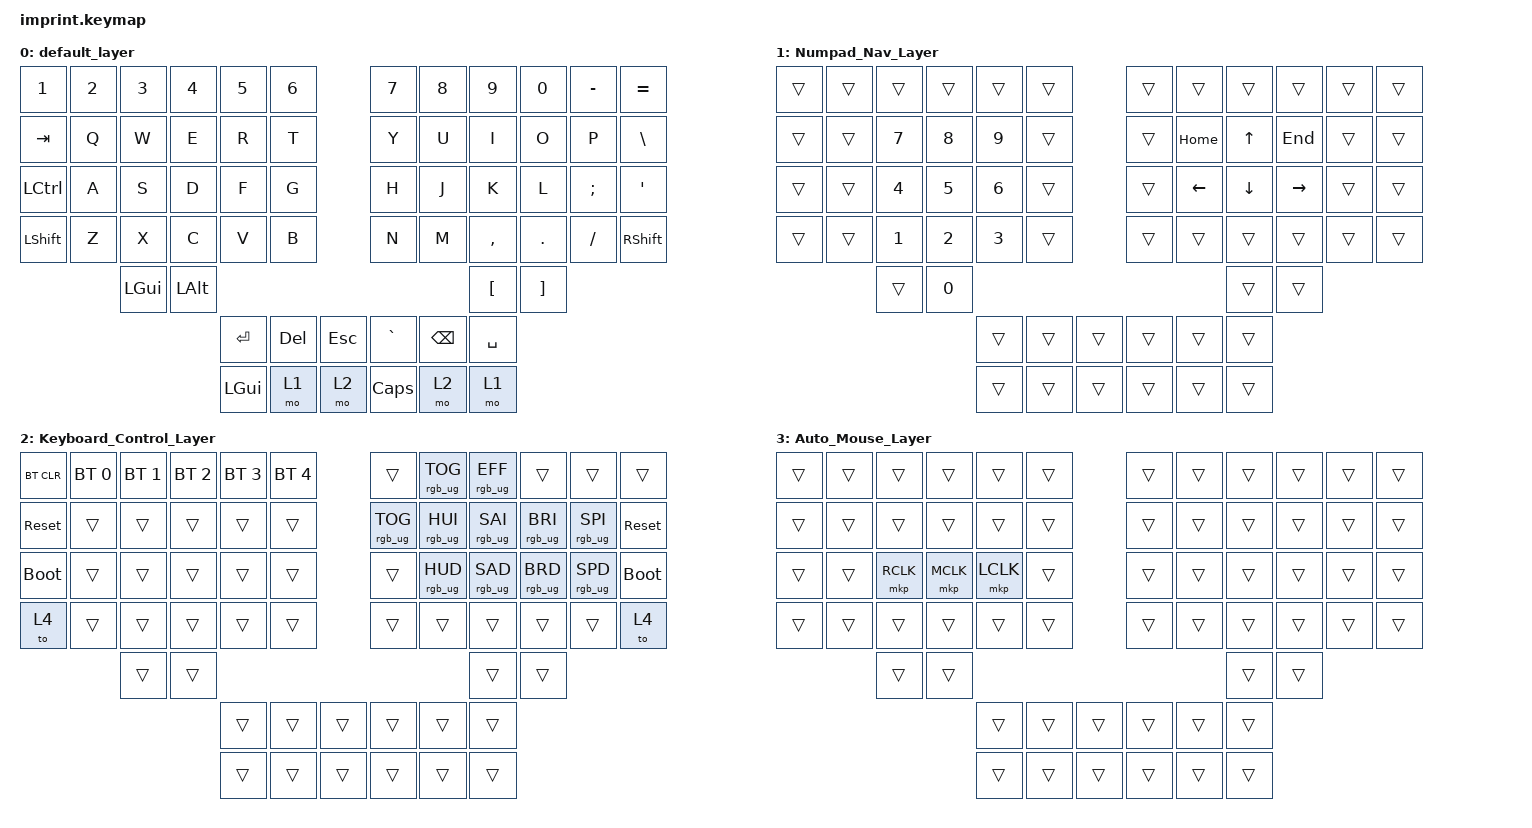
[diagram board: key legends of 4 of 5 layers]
#include <input/processors.dtsi>
#include <dt-bindings/zmk/input_transform.h>
#include <behaviors.dtsi>
#include <dt-bindings/zmk/bt.h>
#include <dt-bindings/zmk/keys.h>
#include <dt-bindings/zmk/pointing.h>
#include <dt-bindings/zmk/rgb.h>

#include "imprint-layout.dtsi"
/ {
//    chosen { zmk,matrix-transform = &imprint_function_row_full_bottom_row; };

    keymap {
        compatible = "zmk,keymap";

        default_layer {
            bindings = <
&kp N1  &kp N2    &kp N3    &kp N4    &kp N5              &kp N6     &kp N7    &kp N8     &kp N9    &kp N0    &kp MINUS &kp EQUAL
&kp TAB    &kp Q   &kp W     &kp E     &kp R     &kp T               &kp Y      &kp U     &kp I      &kp O     &kp P     &kp BSLH
&kp LCTRL  &kp A   &kp S     &kp D     &kp F     &kp G               &kp H      &kp J     &kp K      &kp L     &kp SEMI  &kp SQT
&kp LSHFT  &kp Z   &kp X     &kp C     &kp V     &kp B               &kp N      &kp M     &kp COMMA  &kp DOT   &kp FSLH  &kp RSHFT
                &kp LGUI  &kp LALT                                                        &kp LBKT   &kp RBKT
                                       &kp RET   &kp DEL  &kp ESC    &kp GRAVE  &kp BSPC  &kp SPACE
                                       &kp LGUI  &mo 1    &mo 2      &kp CAPS   &mo 2     &mo 1
            >;
        };

        Numpad_Nav_Layer {
            bindings = <
&trans  &trans  &trans  &trans  &trans  &trans            &trans  &trans    &trans    &trans     &trans  &trans
&trans  &trans  &kp N7  &kp N8  &kp N9  &trans            &trans  &kp HOME  &kp UP    &kp END    &trans  &trans
&trans  &trans  &kp N4  &kp N5  &kp N6  &trans            &trans  &kp LEFT  &kp DOWN  &kp RIGHT  &trans  &trans
&trans  &trans  &kp N1  &kp N2  &kp N3  &trans            &trans  &trans    &trans    &trans     &trans  &trans
                &trans  &kp N0                                              &trans    &trans
                                &trans  &trans  &trans    &trans  &trans    &trans
                                &trans  &trans  &trans    &trans  &trans    &trans
            >;
        };

        Keyboard_Control_Layer {
            bindings = <
&bt BT_CLR   &bt BT_SEL 0  &bt BT_SEL 1  &bt BT_SEL 2  &bt BT_SEL 3  &bt BT_SEL 4            &trans  &rgb_ug RGB_TOG  &rgb_ug RGB_EFF  &trans           &trans           &trans
&sys_reset   &trans        &trans        &trans        &trans        &trans                  &rgb_ug RGB_TOG  &rgb_ug RGB_HUI  &rgb_ug RGB_SAI  &rgb_ug RGB_BRI  &rgb_ug RGB_SPI  &sys_reset
&bootloader  &trans        &trans        &trans        &trans        &trans                  &trans  &rgb_ug RGB_HUD  &rgb_ug RGB_SAD  &rgb_ug RGB_BRD  &rgb_ug RGB_SPD  &bootloader
&to 4        &trans        &trans        &trans        &trans        &trans                  &trans  &trans           &trans           &trans           &trans           &to 4
                            &trans        &trans                                                                     &trans           &trans
                                                       &trans        &trans        &trans    &trans  &trans           &trans
                                                       &trans        &trans        &trans    &trans  &trans           &trans
            >;
        };

        Auto_Mouse_Layer {
            bindings = <
&trans  &trans  &trans     &trans     &trans     &trans            &trans  &trans  &trans  &trans  &trans  &trans
&trans  &trans  &trans     &trans     &trans     &trans            &trans  &trans  &trans  &trans  &trans  &trans
&trans  &trans  &mkp RCLK  &mkp MCLK  &mkp LCLK  &trans            &trans  &trans  &trans  &trans  &trans  &trans
&trans  &trans  &trans     &trans     &trans     &trans            &trans  &trans  &trans  &trans  &trans  &trans
                &trans     &trans                                                    &trans  &trans
                                      &trans     &trans  &trans    &trans  &trans  &trans
                                      &trans     &trans  &trans    &trans  &trans  &trans
            >;
        };

        factory_test {
            bindings = <
&kp N0  &kp N1  &kp N2  &kp N3  &kp N4  &kp N5            &kp N6  &kp N7  &kp N8  &kp N9  &kp N0  &kp N1
&kp N2  &kp N3  &kp N4  &kp N5  &kp N6  &kp N7            &kp N8  &kp N9  &kp N0  &kp N1  &kp N2  &kp N3
&kp N4  &kp N5  &kp N6  &kp N7  &kp N8  &kp N9            &kp N0  &kp N1  &kp N2  &kp N3  &kp N4  &kp N5
&kp N6  &kp N7  &kp N8  &kp N9  &kp N0  &kp N1            &kp N2  &kp N3  &kp N4  &kp N5  &kp N6  &kp N7
&kp N8  &kp N9  &kp N0  &kp N1  &kp N2  &kp N3            &kp N4  &kp N5  &kp N6  &kp N7  &kp N8  &kp N9
                &kp N2  &kp N3                                              &kp N7  &kp N8
                                &kp N1  &kp N2  &kp N3    &kp N4  &kp N5  &kp N6
                                &kp N7  &kp N8  &kp N9    &kp N0  &kp N1  &kp N2
            >;
        };
    };
};
